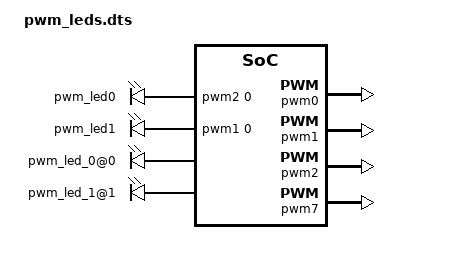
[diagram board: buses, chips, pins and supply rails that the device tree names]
/* Copyright 2022 The Chromium OS Authors. All rights reserved.
 * Use of this source code is governed by a BSD-style license that can be
 * found in the LICENSE file.
 */

/ {
	pwmleds {
		compatible = "pwm-leds";
		pwm_led0: pwm_led_0 {
			pwms = <&pwm2 0 PWM_HZ(4800) PWM_POLARITY_INVERTED
				&pwm0 0 PWM_HZ(4800) PWM_POLARITY_INVERTED>;
		};
		pwm_led1: pwm_led_1 {
			pwms = <&pwm1 0 PWM_HZ(4800) PWM_POLARITY_INVERTED
				&pwm7 0 PWM_HZ(4800) PWM_POLARITY_INVERTED>;
		};
	};

	cros-pwmleds {
		compatible = "cros-ec,pwm-leds";

		leds = <&pwm_led0 &pwm_led1>;
		frequency = <4800>;

			      /*<amber   white>*/
		color-map-red    = <0    0>;
		color-map-green  = <0    0>;
		color-map-blue   = <0    0>;
		color-map-yellow = <0    0>;
		color-map-white  = <0   50>;
		color-map-amber  = <50   0>;

		brightness-range = <0 0 0 0 100 100>;

		#address-cells = <1>;
		#size-cells = <0>;

		pwm_led_0@0 {
			reg = <0>;
			ec-led-name = "EC_LED_ID_LEFT_LED";
		};

		pwm_led_1@1 {
			reg = <1>;
			ec-led-name = "EC_LED_ID_RIGHT_LED";
		};
	};
};

/* LED2 */
&pwm0 {
	status = "okay";
	clock-bus = "NPCX_CLOCK_BUS_LFCLK";
};

/* LED3 */
&pwm1 {
	status = "okay";
	clock-bus = "NPCX_CLOCK_BUS_LFCLK";
};

/* LED1 */
&pwm2 {
	status = "okay";
	clock-bus = "NPCX_CLOCK_BUS_LFCLK";
};

/* LED4 */
&pwm7 {
	status = "okay";
	clock-bus = "NPCX_CLOCK_BUS_LFCLK";
};
